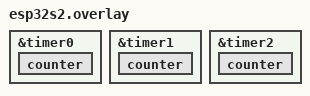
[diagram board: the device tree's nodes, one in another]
/*
 * Copyright (c) 2025-2026 Espressif Systems (Shanghai) Co., Ltd.
 *
 * SPDX-License-Identifier: Apache-2.0
 */

/*
 * Only enable the timers; their interrupt wiring is inherited from
 * esp32s2_common.dtsi, which routes each one through its own INTMUX node with a
 * single interrupt cell. Do not override "interrupts" here: the pre-INTMUX
 * <cpu_line source priority flags> form parses as four separate interrupts
 * against a 1-cell intmux and makes gen_isr_tables.py reject the build.
 */

&timer0 {
	status = "okay";

	counter {
		status = "okay";
	};
};

&timer1 {
	status = "okay";

	counter {
		status = "okay";
	};
};

&timer2 {
	status = "okay";

	counter {
		status = "okay";
	};
};
